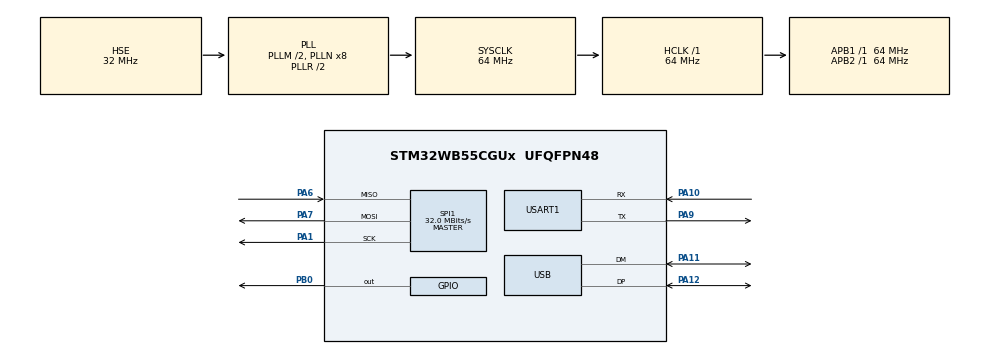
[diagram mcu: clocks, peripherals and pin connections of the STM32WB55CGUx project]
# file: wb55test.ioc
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Mcu.Family=STM32WB
Mcu.Name=STM32WB55CGUx
Mcu.Package=UFQFPN48
NVIC.HSEM_IRQn=true\:0\:0\:false\:false\:true\:false\:true\:true
NVIC.IPCC_C1_RX_IRQn=true\:0\:0\:false\:false\:true\:true\:true\:true
NVIC.IPCC_C1_TX_IRQn=true\:0\:0\:false\:false\:true\:true\:true\:true
NVIC.PriorityGroup=NVIC_PRIORITYGROUP_4
NVIC.RCC_IRQn=true\:0\:0\:false\:false\:true\:true\:false\:true
OSC_IN.Mode=HSE-External-Oscillator
OSC_IN.Signal=RCC_OSC_IN
OSC_OUT.Mode=HSE-External-Oscillator
OSC_OUT.Signal=RCC_OSC_OUT
PA1.Mode=Full_Duplex_Master
PA1.Signal=SPI1_SCK
PA10.Mode=Asynchronous
PA10.Signal=USART1_RX
PA11.Mode=Device
PA11.Signal=USB_DM
PA12.Mode=Device
PA12.Signal=USB_DP
PA13.Mode=Serial_Wire
PA13.Signal=SYS_JTMS-SWDIO
PA14.Mode=Serial_Wire
PA14.Signal=SYS_JTCK-SWCLK
PA6.Mode=Full_Duplex_Master
PA6.Signal=SPI1_MISO
PA7.Mode=Full_Duplex_Master
PA7.Signal=SPI1_MOSI
PA9.Mode=Asynchronous
PA9.Signal=USART1_TX
PB0.Signal=GPIO_Output
ProjectManager.HeapSize=0x200
ProjectManager.StackSize=0x400
ProjectManager.TargetToolchain=CMake
RCC.ADCFreq_Value=48000000
RCC.AHB2CLKDivider=RCC_SYSCLK_DIV2
RCC.AHBFreq_Value=64000000
RCC.APB1Freq_Value=64000000
RCC.APB1TimFreq_Value=64000000
RCC.APB2Freq_Value=64000000
RCC.APB2TimFreq_Value=64000000
RCC.APB3Freq_Value=16000000
RCC.CortexFreq_Value=64000000
RCC.HCLKFreq_Value=64000000
RCC.HSE_VALUE=32000000
RCC.HSI48_VALUE=48000000
RCC.HSI_VALUE=16000000
RCC.LSE_VALUE=32768
RCC.PLLM=RCC_PLLM_DIV2
RCC.PLLSAI1N=6
RCC.PLLSourceVirtual=RCC_PLLSOURCE_HSE
RCC.RNGCLockSelection=RCC_RNGCLKSOURCE_CLK48
RCC.RTCClockSelection=RCC_RTCCLKSOURCE_HSE_DIV32
RCC.SYSCLKFreq_VALUE=64000000
RCC.SYSCLKSource=RCC_SYSCLKSOURCE_PLLCLK
RCC.USBFreq_Value=48000000
RCC.VCOOutputFreq_Value=128000000
RF1.Mode=RF1_Activate
RF1.Signal=RF_RF1
SPI1.BaudRatePrescaler=SPI_BAUDRATEPRESCALER_2
SPI1.CalculateBaudRate=32.0 MBits/s
SPI1.Direction=SPI_DIRECTION_2LINES
SPI1.Mode=SPI_MODE_MASTER
SPI1.VirtualType=VM_MASTER
STM32_WPAN.CFG_LSCLK_LSE=0
USART1.VirtualMode-Asynchronous=VM_ASYNC
VP_HSEM_VS_HSEM.Mode=HSEM_Activate
VP_IPCC_VS_IPCC.Mode=IPCC_Activate
VP_MEMORYMAP_VS_MEMORYMAP.Mode=CurAppReg
VP_RNG_VS_RNG.Mode=RNG_Activate
VP_RTC_VS_RTC_Activate.Mode=RTC_Enabled
VP_SEQUENCER_VS_SEQUENCER.Mode=SEQUENCER_Enabled
VP_STM32_WPAN_VS_BLE_HOST.Mode=STM32_WPAN_Enabled
VP_TINY_LPM_VS_TINY_LPM.Mode=TINY_LPM_Enabled
board=custom

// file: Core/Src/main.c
/* USER CODE BEGIN Header */
/**
  ******************************************************************************
  * @file           : main.c
  * @brief          : Main program body
  ******************************************************************************
  * @attention
  *
  * Copyright (c) 2026 STMicroelectronics.
  * All rights reserved.
  *
  * This software is licensed under terms that can be found in the LICENSE file
  * in the root directory of this software component.
  * If no LICENSE file comes with this software, it is provided AS-IS.
  *
  ******************************************************************************
  */
/* USER CODE END Header */
#include "main.h"

IPCC_HandleTypeDef hipcc;

RNG_HandleTypeDef hrng;

RTC_HandleTypeDef hrtc;

SPI_HandleTypeDef hspi1;

UART_HandleTypeDef huart1;

PCD_HandleTypeDef hpcd_USB_FS;

/* USER CODE BEGIN PV */
static uint32_t led_tick;
/* USER CODE END PV */

void SystemClock_Config(void);
void PeriphCommonClock_Config(void);
static void MX_GPIO_Init(void);
static void MX_SPI1_Init(void);
static void MX_USART1_UART_Init(void);
static void MX_USB_PCD_Init(void);
static void MX_IPCC_Init(void);
static void MX_RTC_Init(void);
static void MX_RNG_Init(void);
static void MX_RF_Init(void);

int main(void)
{

  /* MCU Configuration--------------------------------------------------------*/

  /* Reset of all peripherals, Initializes the Flash interface and the Systick. */
  HAL_Init();
  /* Config code for STM32_WPAN (HSE Tuning must be done before system clock configuration) */
  MX_APPE_Config();

  /* Configure the system clock */
  SystemClock_Config();

  /* Configure the peripherals common clocks */
  PeriphCommonClock_Config();

  /* IPCC initialisation */
  MX_IPCC_Init();

  /* Initialize all configured peripherals */
  MX_GPIO_Init();
  MX_SPI1_Init();
  MX_USART1_UART_Init();
  MX_USB_PCD_Init();
  MX_RTC_Init();
  MX_RNG_Init();
  MX_RF_Init();

  /* Init code for STM32_WPAN */
  MX_APPE_Init();

  /* Infinite loop */
  while (1)
  {
    MX_APPE_Process();

    /* USER CODE BEGIN 3 */
    if ((HAL_GetTick() - led_tick) >= 500U)
    {
        led_tick = HAL_GetTick();
        HAL_GPIO_TogglePin(GPIOB, GPIO_PIN_0);
    }
  }
  /* USER CODE END 3 */
}

void SystemClock_Config(void)
{
  RCC_OscInitTypeDef RCC_OscInitStruct = {0};
  RCC_ClkInitTypeDef RCC_ClkInitStruct = {0};

  /** Configure the main internal regulator output voltage
  */
  __HAL_PWR_VOLTAGESCALING_CONFIG(PWR_REGULATOR_VOLTAGE_SCALE1);

  /** Initializes the RCC Oscillators according to the specified parameters
  * in the RCC_OscInitTypeDef structure.
  */
  RCC_OscInitStruct.OscillatorType = RCC_OSCILLATORTYPE_HSI|RCC_OSCILLATORTYPE_HSE;
  RCC_OscInitStruct.HSEState = RCC_HSE_ON;
  RCC_OscInitStruct.HSIState = RCC_HSI_ON;
  RCC_OscInitStruct.HSICalibrationValue = RCC_HSICALIBRATION_DEFAULT;
  RCC_OscInitStruct.PLL.PLLState = RCC_PLL_ON;
  RCC_OscInitStruct.PLL.PLLSource = RCC_PLLSOURCE_HSE;
  RCC_OscInitStruct.PLL.PLLM = RCC_PLLM_DIV2;
  RCC_OscInitStruct.PLL.PLLN = 8;
  RCC_OscInitStruct.PLL.PLLP = RCC_PLLP_DIV2;
  RCC_OscInitStruct.PLL.PLLR = RCC_PLLR_DIV2;
  RCC_OscInitStruct.PLL.PLLQ = RCC_PLLQ_DIV2;
  if (HAL_RCC_OscConfig(&RCC_OscInitStruct) != HAL_OK)
  {
    Error_Handler();
  }

  /** Configure the SYSCLKSource, HCLK, PCLK1 and PCLK2 clocks dividers
  */
  RCC_ClkInitStruct.ClockType = RCC_CLOCKTYPE_HCLK4|RCC_CLOCKTYPE_HCLK2
                              |RCC_CLOCKTYPE_HCLK|RCC_CLOCKTYPE_SYSCLK
                              |RCC_CLOCKTYPE_PCLK1|RCC_CLOCKTYPE_PCLK2;
  RCC_ClkInitStruct.SYSCLKSource = RCC_SYSCLKSOURCE_PLLCLK;
  RCC_ClkInitStruct.AHBCLKDivider = RCC_SYSCLK_DIV1;
  RCC_ClkInitStruct.APB1CLKDivider = RCC_HCLK_DIV1;
  RCC_ClkInitStruct.APB2CLKDivider = RCC_HCLK_DIV1;
  RCC_ClkInitStruct.AHBCLK2Divider = RCC_SYSCLK_DIV2;
  RCC_ClkInitStruct.AHBCLK4Divider = RCC_SYSCLK_DIV1;

  if (HAL_RCC_ClockConfig(&RCC_ClkInitStruct, FLASH_LATENCY_3) != HAL_OK)
  {
    Error_Handler();
  }
}

void PeriphCommonClock_Config(void)
{
  RCC_PeriphCLKInitTypeDef PeriphClkInitStruct = {0};

  /** Initializes the peripherals clock
  */
  PeriphClkInitStruct.PeriphClockSelection = RCC_PERIPHCLK_SMPS|RCC_PERIPHCLK_RFWAKEUP
                              |RCC_PERIPHCLK_CLK48SEL|RCC_PERIPHCLK_USB
                              |RCC_PERIPHCLK_RNG;
  PeriphClkInitStruct.PLLSAI1.PLLN = 6;
  PeriphClkInitStruct.PLLSAI1.PLLP = RCC_PLLP_DIV2;
  PeriphClkInitStruct.PLLSAI1.PLLQ = RCC_PLLQ_DIV2;
  PeriphClkInitStruct.PLLSAI1.PLLR = RCC_PLLR_DIV2;
  PeriphClkInitStruct.PLLSAI1.PLLSAI1ClockOut = RCC_PLLSAI1_USBCLK;
  PeriphClkInitStruct.UsbClockSelection = RCC_USBCLKSOURCE_PLLSAI1;
  PeriphClkInitStruct.RngClockSelection = RCC_RNGCLKSOURCE_PLLSAI1;
  PeriphClkInitStruct.RFWakeUpClockSelection = RCC_RFWKPCLKSOURCE_HSE_DIV1024;
  PeriphClkInitStruct.SmpsClockSelection = RCC_SMPSCLKSOURCE_HSI;
  PeriphClkInitStruct.SmpsDivSelection = RCC_SMPSCLKDIV_RANGE1;

  if (HAL_RCCEx_PeriphCLKConfig(&PeriphClkInitStruct) != HAL_OK)
  {
    Error_Handler();
  }
}

static void MX_IPCC_Init(void)
{

  hipcc.Instance = IPCC;
  if (HAL_IPCC_Init(&hipcc) != HAL_OK)
  {
    Error_Handler();
  }

}

static void MX_RF_Init(void)
{

}

static void MX_RNG_Init(void)
{

  hrng.Instance = RNG;
  hrng.Init.ClockErrorDetection = RNG_CED_ENABLE;
  if (HAL_RNG_Init(&hrng) != HAL_OK)
  {
    Error_Handler();
  }

}

static void MX_RTC_Init(void)
{

  /** Initialize RTC Only
  */
  hrtc.Instance = RTC;
  hrtc.Init.HourFormat = RTC_HOURFORMAT_24;
  hrtc.Init.AsynchPrediv = CFG_RTC_ASYNCH_PRESCALER;
  hrtc.Init.SynchPrediv = CFG_RTC_SYNCH_PRESCALER;
  hrtc.Init.OutPut = RTC_OUTPUT_DISABLE;
  hrtc.Init.OutPutPolarity = RTC_OUTPUT_POLARITY_HIGH;
  hrtc.Init.OutPutType = RTC_OUTPUT_TYPE_OPENDRAIN;
  hrtc.Init.OutPutRemap = RTC_OUTPUT_REMAP_NONE;
  if (HAL_RTC_Init(&hrtc) != HAL_OK)
  {
    Error_Handler();
  }

}

static void MX_SPI1_Init(void)
{

  /* SPI1 parameter configuration*/
  hspi1.Instance = SPI1;
  hspi1.Init.Mode = SPI_MODE_MASTER;
  hspi1.Init.Direction = SPI_DIRECTION_2LINES;
  hspi1.Init.DataSize = SPI_DATASIZE_4BIT;
  hspi1.Init.CLKPolarity = SPI_POLARITY_LOW;
  hspi1.Init.CLKPhase = SPI_PHASE_1EDGE;
  hspi1.Init.NSS = SPI_NSS_SOFT;
  hspi1.Init.BaudRatePrescaler = SPI_BAUDRATEPRESCALER_2;
  hspi1.Init.FirstBit = SPI_FIRSTBIT_MSB;
  hspi1.Init.TIMode = SPI_TIMODE_DISABLE;
  hspi1.Init.CRCCalculation = SPI_CRCCALCULATION_DISABLE;
  hspi1.Init.CRCPolynomial = 7;
  hspi1.Init.CRCLength = SPI_CRC_LENGTH_DATASIZE;
  hspi1.Init.NSSPMode = SPI_NSS_PULSE_ENABLE;
  if (HAL_SPI_Init(&hspi1) != HAL_OK)
  {
    Error_Handler();
  }

}

static void MX_USART1_UART_Init(void)
{

  huart1.Instance = USART1;
  huart1.Init.BaudRate = 115200;
  huart1.Init.WordLength = UART_WORDLENGTH_8B;
  huart1.Init.StopBits = UART_STOPBITS_1;
  huart1.Init.Parity = UART_PARITY_NONE;
  huart1.Init.Mode = UART_MODE_TX_RX;
  huart1.Init.HwFlowCtl = UART_HWCONTROL_NONE;
  huart1.Init.OverSampling = UART_OVERSAMPLING_16;
  huart1.Init.OneBitSampling = UART_ONE_BIT_SAMPLE_DISABLE;
  huart1.Init.ClockPrescaler = UART_PRESCALER_DIV1;
  huart1.AdvancedInit.AdvFeatureInit = UART_ADVFEATURE_NO_INIT;
  if (HAL_UART_Init(&huart1) != HAL_OK)
  {
    Error_Handler();
  }
  if (HAL_UARTEx_SetTxFifoThreshold(&huart1, UART_TXFIFO_THRESHOLD_1_8) != HAL_OK)
  {
    Error_Handler();
  }
  if (HAL_UARTEx_SetRxFifoThreshold(&huart1, UART_RXFIFO_THRESHOLD_1_8) != HAL_OK)
  {
    Error_Handler();
  }
  if (HAL_UARTEx_DisableFifoMode(&huart1) != HAL_OK)
  {
    Error_Handler();
  }

}

static void MX_USB_PCD_Init(void)
{

  hpcd_USB_FS.Instance = USB;
  hpcd_USB_FS.Init.dev_endpoints = 8;
  hpcd_USB_FS.Init.speed = PCD_SPEED_FULL;
  hpcd_USB_FS.Init.phy_itface = PCD_PHY_EMBEDDED;
  hpcd_USB_FS.Init.Sof_enable = DISABLE;
  hpcd_USB_FS.Init.low_power_enable = DISABLE;
  hpcd_USB_FS.Init.lpm_enable = DISABLE;
  hpcd_USB_FS.Init.battery_charging_enable = DISABLE;
  if (HAL_PCD_Init(&hpcd_USB_FS) != HAL_OK)
  {
    Error_Handler();
  }

}

static void MX_GPIO_Init(void)
{
  GPIO_InitTypeDef GPIO_InitStruct = {0};

  /* GPIO Ports Clock Enable */
  __HAL_RCC_GPIOA_CLK_ENABLE();
  __HAL_RCC_GPIOB_CLK_ENABLE();

  /*Configure GPIO pin Output Level */
  HAL_GPIO_WritePin(GPIOB, GPIO_PIN_0, GPIO_PIN_RESET);

  /*Configure GPIO pin : PB0 */
  GPIO_InitStruct.Pin = GPIO_PIN_0;
  GPIO_InitStruct.Mode = GPIO_MODE_OUTPUT_PP;
  GPIO_InitStruct.Pull = GPIO_NOPULL;
  GPIO_InitStruct.Speed = GPIO_SPEED_FREQ_LOW;
  HAL_GPIO_Init(GPIOB, &GPIO_InitStruct);

}

void Error_Handler(void)
{
  __disable_irq();
  while (1)
  {
  }
}
